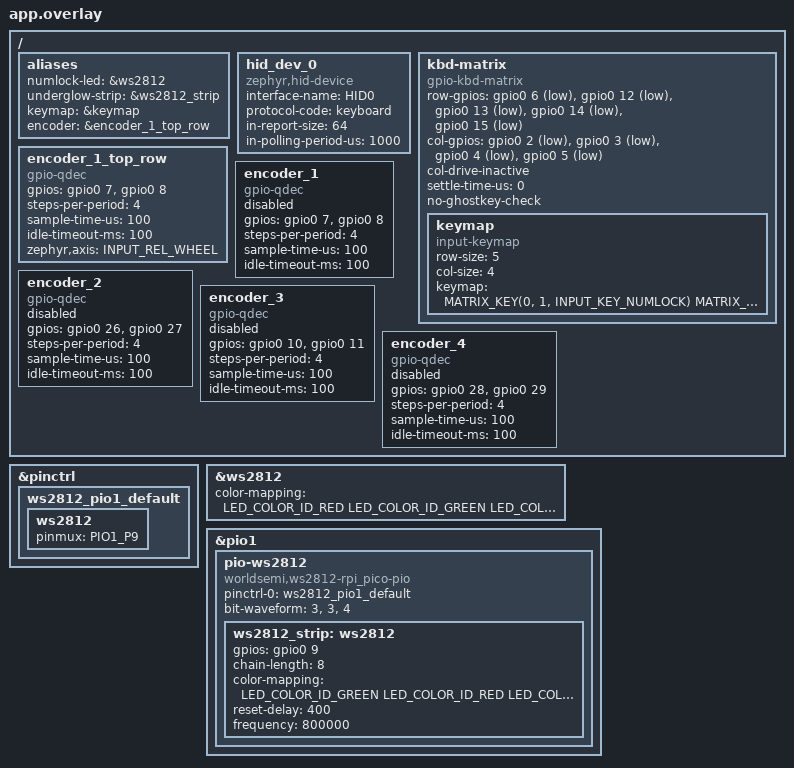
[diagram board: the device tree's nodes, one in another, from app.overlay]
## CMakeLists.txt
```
cmake_minimum_required(VERSION 3.20.0)

set(BOARD rp2040_zero)
find_package(Zephyr)

project(tidbit-gateron)

target_sources(app PRIVATE
  src/main.c
  src/usbd_init.c
)
```

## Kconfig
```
# Copyright (c) 2023 Nordic Semiconductor ASA
# SPDX-License-Identifier: Apache-2.0

menu "USB options"
	depends on USB_DEVICE_STACK_NEXT

config USBD_MANUFACTURER
	string "USB device manufacturer string"
	default "Zephyr Project"
	help
	  USB device manufacturer string.

config USBD_PRODUCT
	string "USB device sample product string"
	default "USBD sample"
	help
	  USB device product stringa.

config USBD_VID
	hex "USB device Vendor ID"
	default 0x2fe3
	help
	  USB device Vendor ID.
	  Zephyr project vendor ID must not be used outside of Zephyr samples.

config USBD_PID
	hex "USB device Product ID"
	default 0x0001
	help
	  USB device Product ID.

config USBD_SELF_POWERED
	bool "USB device Self-powered attribute"
	default y
	help
	  Set the Self-powered attribute in the configuration.

config USBD_REMOTE_WAKEUP
	bool "USB device Remote Wakeup attribute"
	help
	  Set the Remote Wakeup attribute in the configuration.

config USBD_MAX_POWER
	int "USB device bMaxPower value"
	default 125
	range 0 250
	help
	  bMaxPower value in the configuration in 2 mA units.

config USBD_20_EXTENSION_DESC
	bool "Use default USB 2.0 Extension Descriptor"
	help
	  Set bcdUSB value to 0201 and use default USB 2.0 Extension Descriptor.

endmenu

config ENCODER_INVERSE
	bool "Inverse rotary encoder readings"
	help
	  Inverse rotary encoder readings.

source "Kconfig.zephyr"
```

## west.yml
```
manifest:
  remotes:
    - name: zephyrproject-rtos
      url-base: https://github.com/zephyrproject-rtos
  projects:
    - name: zephyr
      remote: zephyrproject-rtos
      revision: v4.1.0
      import:
        name-allowlist:
          - hal_rpi_pico
```

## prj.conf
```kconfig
CONFIG_USB_DEVICE_STACK_NEXT=y
CONFIG_USBD_HID_SUPPORT=y

CONFIG_LOG=y
CONFIG_USBD_LOG_LEVEL_WRN=y
CONFIG_USBD_HID_LOG_LEVEL_WRN=y
CONFIG_UDC_DRIVER_LOG_LEVEL_WRN=y

# VID/PID comes from the used board.
# See: https://github.com/raspberrypi/usb-pid
CONFIG_USBD_VID=0x2E8A
CONFIG_USBD_PID=0x101F
CONFIG_USBD_MANUFACTURER="dseight"
CONFIG_USBD_PRODUCT="tidbit-gateron numpad"

CONFIG_GPIO=y
CONFIG_INPUT=y
CONFIG_INPUT_MODE_SYNCHRONOUS=y

# Inverse rotary encoder readings. Enable for the GREEN encoder.
# CONFIG_ENCODER_INVERSE=y

CONFIG_LED_STRIP=y
```

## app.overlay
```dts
#include <dt-bindings/i2c/i2c.h>
#include <dt-bindings/pinctrl/rpi-pico-rp2040-pinctrl.h>
#include <zephyr/dt-bindings/input/input-event-codes.h>
#include <zephyr/dt-bindings/input/keymap.h>

/ {
	aliases {
		/*
		 * rp2040_zero has a single on-board led, which has "led-strip" alias.
		 * Redefine it as just "led" to reduce confusion.
		 */
		/delete-property/ led-strip;
		numlock-led = &ws2812;
		underglow-strip = &ws2812_strip;
		keymap = &keymap;
		encoder = &encoder_1_top_row;
	};

	hid_dev_0: hid_dev_0 {
		compatible = "zephyr,hid-device";
		interface-name = "HID0";
		protocol-code = "keyboard";
		in-report-size = <64>;
		in-polling-period-us = <1000>;
	};

	kbd-matrix {
		compatible = "gpio-kbd-matrix";
		row-gpios = <&gpio0  6 (GPIO_PULL_UP | GPIO_ACTIVE_LOW)>,
			    <&gpio0 12 (GPIO_PULL_UP | GPIO_ACTIVE_LOW)>,
			    <&gpio0 13 (GPIO_PULL_UP | GPIO_ACTIVE_LOW)>,
			    <&gpio0 14 (GPIO_PULL_UP | GPIO_ACTIVE_LOW)>,
			    <&gpio0 15 (GPIO_PULL_UP | GPIO_ACTIVE_LOW)>;
		col-gpios = <&gpio0 2 GPIO_ACTIVE_LOW>,
			    <&gpio0 3 GPIO_ACTIVE_LOW>,
			    <&gpio0 4 GPIO_ACTIVE_LOW>,
			    <&gpio0 5 GPIO_ACTIVE_LOW>;
		col-drive-inactive;
		settle-time-us = <0>;
		no-ghostkey-check;

		keymap: keymap {
			compatible = "input-keymap";
			row-size = <5>;
			col-size = <4>;
			keymap = <
				MATRIX_KEY(0, 1, INPUT_KEY_NUMLOCK)
				MATRIX_KEY(0, 2, INPUT_KEY_KPSLASH)
				MATRIX_KEY(0, 3, INPUT_KEY_KPASTERISK)

				MATRIX_KEY(1, 0, INPUT_KEY_KP7)
				MATRIX_KEY(1, 1, INPUT_KEY_KP8)
				MATRIX_KEY(1, 2, INPUT_KEY_KP9)
				MATRIX_KEY(1, 3, INPUT_KEY_KPMINUS)

				MATRIX_KEY(2, 0, INPUT_KEY_KP4)
				MATRIX_KEY(2, 1, INPUT_KEY_KP5)
				MATRIX_KEY(2, 2, INPUT_KEY_KP6)
				MATRIX_KEY(2, 3, INPUT_KEY_KPPLUS)

				MATRIX_KEY(3, 0, INPUT_KEY_KP1)
				MATRIX_KEY(3, 1, INPUT_KEY_KP2)
				MATRIX_KEY(3, 2, INPUT_KEY_KP3)
				MATRIX_KEY(3, 3, INPUT_KEY_KPENTER)

				MATRIX_KEY(4, 0, INPUT_KEY_BACKSPACE)
				MATRIX_KEY(4, 1, INPUT_KEY_KP0)
				MATRIX_KEY(4, 2, INPUT_KEY_DOT)
				MATRIX_KEY(4, 3, INPUT_KEY_SYSRQ)
			>;
		};
	};

	encoder_1_top_row: encoder_1_top_row {
		compatible = "gpio-qdec";
		gpios = <&gpio0 7 (GPIO_PULL_UP | GPIO_ACTIVE_HIGH)>,
			<&gpio0 8 (GPIO_PULL_UP | GPIO_ACTIVE_HIGH)>;
		steps-per-period = <4>;
		sample-time-us = <100>;
		idle-timeout-ms = <100>;
		zephyr,axis = <INPUT_REL_WHEEL>;
	};

	encoder_1: encoder_1 {
		compatible = "gpio-qdec";
		gpios = <&gpio0 7 (GPIO_PULL_UP | GPIO_ACTIVE_HIGH)>,
			<&gpio0 8 (GPIO_PULL_UP | GPIO_ACTIVE_HIGH)>;
		steps-per-period = <4>;
		sample-time-us = <100>;
		idle-timeout-ms = <100>;
		status = "disabled";
	};

	encoder_2: encoder_2 {
		compatible = "gpio-qdec";
		gpios = <&gpio0 26 (GPIO_PULL_UP | GPIO_ACTIVE_HIGH)>,
			<&gpio0 27 (GPIO_PULL_UP | GPIO_ACTIVE_HIGH)>;
		steps-per-period = <4>;
		sample-time-us = <100>;
		idle-timeout-ms = <100>;
		status = "disabled";
	};

	encoder_3: encoder_3 {
		compatible = "gpio-qdec";
		gpios = <&gpio0 10 (GPIO_PULL_UP | GPIO_ACTIVE_HIGH)>,
			<&gpio0 11 (GPIO_PULL_UP | GPIO_ACTIVE_HIGH)>;
		steps-per-period = <4>;
		sample-time-us = <100>;
		idle-timeout-ms = <100>;
		status = "disabled";
	};

	encoder_4: encoder_4 {
		compatible = "gpio-qdec";
		gpios = <&gpio0 28 (GPIO_PULL_UP | GPIO_ACTIVE_HIGH)>,
			<&gpio0 29 (GPIO_PULL_UP | GPIO_ACTIVE_HIGH)>;
		steps-per-period = <4>;
		sample-time-us = <100>;
		idle-timeout-ms = <100>;
		status = "disabled";
	};
};

&pinctrl {
	ws2812_pio1_default: ws2812_pio1_default {
		ws2812 {
			pinmux = <PIO1_P9>;
		};
	};
};

&ws2812 {
	/* Color mapping in upstream is wrong */
	color-mapping = <LED_COLOR_ID_RED
			 LED_COLOR_ID_GREEN
			 LED_COLOR_ID_BLUE>;
};

&pio1 {
	status = "okay";

	pio-ws2812 {
		compatible = "worldsemi,ws2812-rpi_pico-pio";
		status = "okay";
		pinctrl-0 = <&ws2812_pio1_default>;
		pinctrl-names = "default";
		bit-waveform = <3>, <3>, <4>;

		ws2812_strip: ws2812 {
			status = "okay";
			gpios = <&gpio0 9 GPIO_ACTIVE_HIGH>;
			chain-length = <8>;
			color-mapping = <LED_COLOR_ID_GREEN
					 LED_COLOR_ID_RED
					 LED_COLOR_ID_BLUE>;
			reset-delay = <400>;
			frequency = <800000>;
		};
	};
};
```

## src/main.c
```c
#include <zephyr/kernel.h>
#include <zephyr/device.h>
#include <zephyr/drivers/gpio.h>
#include <zephyr/drivers/led_strip.h>
#include <zephyr/input/input.h>
#include <zephyr/input/input_hid.h>

#include <zephyr/usb/usbd.h>
#include <zephyr/usb/class/usbd_hid.h>

#include "usbd_init.h"

#define LOG_LEVEL 4
#include <zephyr/logging/log.h>
LOG_MODULE_REGISTER(main);

#define KEYMAP_NODE		DT_ALIAS(keymap)
static const struct device *const keymap_dev = DEVICE_DT_GET(KEYMAP_NODE);

#define ENCODER_NODE		DT_ALIAS(encoder)
static const struct device *const encoder_dev = DEVICE_DT_GET(ENCODER_NODE);

#define UNDERGLOW_NODE		DT_ALIAS(underglow_strip)
static const struct device *const underglow_strip = DEVICE_DT_GET(UNDERGLOW_NODE);

#define NUMLOCK_LED_NODE	DT_ALIAS(numlock_led)
static const struct device *const numlock_led = DEVICE_DT_GET(NUMLOCK_LED_NODE);

#if DT_NODE_HAS_PROP(DT_ALIAS(underglow_strip), chain_length)
#define UNDERGLOW_NUM_PIXELS	DT_PROP(DT_ALIAS(underglow_strip), chain_length)
#else
#error "Unable to determine length of LED strip"
#endif

static struct led_rgb numlock_led_on = {
	.r = 3, .g = 0, .b = 1
};
static struct led_rgb numlock_led_off = {
	.r = 0, .g = 0, .b = 0
};

static const struct led_rgb underglow_idle = {
	.r = 52, .g = 70, .b = 255
};
static const struct led_rgb underglow_numlock_on = {
	.r = 255, .g = 30, .b = 65
};
static struct led_rgb pixels[UNDERGLOW_NUM_PIXELS];

static const uint8_t hid_report_desc[] = HID_KEYBOARD_REPORT_DESC();

enum kb_leds_idx {
	KB_LED_NUMLOCK = 0,
	KB_LED_CAPSLOCK,
	KB_LED_SCROLLLOCK,
	KB_LED_COUNT,
};

enum kb_report_idx {
	KB_MOD_KEY = 0,
	KB_RESERVED,
	KB_KEY_CODE1,
	KB_KEY_CODE2,
	KB_KEY_CODE3,
	KB_KEY_CODE4,
	KB_KEY_CODE5,
	KB_KEY_CODE6,
	KB_REPORT_COUNT,
};

struct kb_event {
	uint8_t type;
	uint16_t code;
	int32_t value;
};

K_MSGQ_DEFINE(kb_msgq, sizeof(struct kb_event), 2, 1);

UDC_STATIC_BUF_DEFINE(report, KB_REPORT_COUNT);
static uint32_t kb_duration;
static bool kb_ready;

static void kb_input_cb(struct input_event *evt, void *user_data)
{
	struct kb_event kb_evt;

	ARG_UNUSED(user_data);

	kb_evt.type = evt->type;
	kb_evt.code = evt->code;
	kb_evt.value = evt->value;
	if (k_msgq_put(&kb_msgq, &kb_evt, K_NO_WAIT) != 0) {
		LOG_ERR("Failed to put new input event");
	}
}
INPUT_CALLBACK_DEFINE(keymap_dev, kb_input_cb, NULL);

static void enc_input_cb(struct input_event *evt, void *user_data)
{
	struct kb_event kb_evt;

	ARG_UNUSED(user_data);

	kb_evt.type = evt->type;
	kb_evt.code = evt->code;
	kb_evt.value = evt->value;
	if (k_msgq_put(&kb_msgq, &kb_evt, K_NO_WAIT) != 0) {
		LOG_ERR("Failed to put new input event");
	}
}
INPUT_CALLBACK_DEFINE(encoder_dev, enc_input_cb, NULL);

static void kb_iface_ready(const struct device *dev, const bool ready)
{
	LOG_INF("HID device %s interface is %s",
		dev->name, ready ? "ready" : "not ready");
	kb_ready = ready;
}

static int kb_get_report(const struct device *dev,
			 const uint8_t type, const uint8_t id, const uint16_t len,
			 uint8_t *const buf)
{
	LOG_WRN("Get Report not implemented, Type %u ID %u", type, id);

	return 0;
}

static int set_underglow_rgb(const struct led_rgb *color)
{
	for (int i = 0; i < UNDERGLOW_NUM_PIXELS; i++)
		pixels[i] = *color;

	return led_strip_update_rgb(underglow_strip, pixels, UNDERGLOW_NUM_PIXELS);
}

static int kb_set_report(const struct device *dev,
			 const uint8_t type, const uint8_t id, const uint16_t len,
			 const uint8_t *const buf)
{
	if (type != HID_REPORT_TYPE_OUTPUT) {
		LOG_WRN("Unsupported report type");
		return -ENOTSUP;
	}

	if (buf[0] & BIT(0)) {
		led_strip_update_rgb(numlock_led, &numlock_led_off, 1);
		set_underglow_rgb(&underglow_idle);
	} else {
		led_strip_update_rgb(numlock_led, &numlock_led_on, 1);
		set_underglow_rgb(&underglow_numlock_on);
	}

	return 0;
}

/* Idle duration is stored but not used to calculate idle reports. */
static void kb_set_idle(const struct device *dev,
			const uint8_t id, const uint32_t duration)
{
	LOG_INF("Set Idle %u to %u", id, duration);
	kb_duration = duration;
}

static uint32_t kb_get_idle(const struct device *dev, const uint8_t id)
{
	LOG_INF("Get Idle %u to %u", id, kb_duration);
	return kb_duration;
}

static void kb_set_protocol(const struct device *dev, const uint8_t proto)
{
	LOG_INF("Protocol changed to %s",
		proto == 0U ? "Boot Protocol" : "Report Protocol");
}

static void kb_output_report(const struct device *dev, const uint16_t len,
			     const uint8_t *const buf)
{
	LOG_HEXDUMP_DBG(buf, len, "o.r.");
	kb_set_report(dev, HID_REPORT_TYPE_OUTPUT, 0U, len, buf);
}

struct hid_device_ops kb_ops = {
	.iface_ready = kb_iface_ready,
	.get_report = kb_get_report,
	.set_report = kb_set_report,
	.set_idle = kb_set_idle,
	.get_idle = kb_get_idle,
	.set_protocol = kb_set_protocol,
	.output_report = kb_output_report,
};

static void msg_cb(struct usbd_context *const usbd_ctx,
		   const struct usbd_msg *const msg)
{
	LOG_INF("USBD message: %s", usbd_msg_type_string(msg->type));

	if (msg->type == USBD_MSG_CONFIGURATION) {
		LOG_INF("\tConfiguration value %d", msg->status);
	}

	if (usbd_can_detect_vbus(usbd_ctx)) {
		if (msg->type == USBD_MSG_VBUS_READY) {
			if (usbd_enable(usbd_ctx)) {
				LOG_ERR("Failed to enable device support");
			}
		}

		if (msg->type == USBD_MSG_VBUS_REMOVED) {
			if (usbd_disable(usbd_ctx)) {
				LOG_ERR("Failed to disable device support");
			}
		}
	}
}

static void handle_kb_event(const struct device *hid_dev,
			    uint16_t code, int32_t value)
{
	int ret;
	int16_t hid_code;

	hid_code = input_to_hid_code(code);
	if (hid_code == -1) {
		LOG_INF("Unrecognized input code %u value %d", code, value);
		return;
	}

	if (value) {
		report[KB_KEY_CODE1] = hid_code;
		report[KB_MOD_KEY] = input_to_hid_modifier(code);
	} else {
		report[KB_KEY_CODE1] = 0;
		report[KB_MOD_KEY] = 0;
	}

	if (!kb_ready) {
		LOG_INF("USB HID device is not ready");
		return;
	}

	ret = hid_device_submit_report(hid_dev, KB_REPORT_COUNT, report);
	if (ret) {
		LOG_ERR("HID submit report error, %d", ret);
	}
}

static void handle_enc_event(const struct device *hid_dev,
			     uint16_t code, int32_t value)
{
	static int enc_events = 0;
	int ret;

	LOG_INF("Encoder event %d value %d", enc_events, value);
	enc_events++;

	if (value != 1 && value != -1) {
		LOG_ERR("Wrong encoder value %d", value);
		return;
	}

	if (IS_ENABLED(CONFIG_ENCODER_INVERSE))
		value = -value;

	report[KB_KEY_CODE1] = HID_KEY_B;
	report[KB_MOD_KEY] = HID_KBD_MODIFIER_LEFT_CTRL;

	ret = hid_device_submit_report(hid_dev, KB_REPORT_COUNT, report);
	if (ret) {
		LOG_ERR("HID submit report error, %d", ret);
		return;
	}

	report[KB_KEY_CODE1] = 0;
	report[KB_MOD_KEY] = 0;

	ret = hid_device_submit_report(hid_dev, KB_REPORT_COUNT, report);
	if (ret) {
		LOG_ERR("HID submit report error, %d", ret);
		return;
	}

	if (value == 1) {
		report[KB_KEY_CODE1] = HID_KEY_N;
		report[KB_MOD_KEY] = 0;
	} else if (value == -1) {
		report[KB_KEY_CODE1] = HID_KEY_P;
		report[KB_MOD_KEY] = 0;
	}

	ret = hid_device_submit_report(hid_dev, KB_REPORT_COUNT, report);
	if (ret) {
		LOG_ERR("HID submit report error, %d", ret);
		return;
	}

	report[KB_KEY_CODE1] = 0;
	report[KB_MOD_KEY] = 0;

	ret = hid_device_submit_report(hid_dev, KB_REPORT_COUNT, report);
	if (ret) {
		LOG_ERR("HID submit report error, %d", ret);
		return;
	}
}

int main(void)
{
	const struct device *hid_dev;
	struct usbd_context *sample_usbd;
	int ret;

	if (!device_is_ready(underglow_strip)) {
		LOG_ERR("LED strip device %s is not ready", underglow_strip->name);
		return 0;
	}

	hid_dev = DEVICE_DT_GET_ONE(zephyr_hid_device);
	if (!device_is_ready(hid_dev)) {
		LOG_ERR("HID Device is not ready");
		return -EIO;
	}

	ret = hid_device_register(hid_dev,
				  hid_report_desc, sizeof(hid_report_desc),
				  &kb_ops);
	if (ret != 0) {
		LOG_ERR("Failed to register HID Device, %d", ret);
		return ret;
	}

	sample_usbd = sample_usbd_init_device(msg_cb);
	if (sample_usbd == NULL) {
		LOG_ERR("Failed to initialize USB device");
		return -ENODEV;
	}

	if (!usbd_can_detect_vbus(sample_usbd)) {
		/* doc device enable start */
		ret = usbd_enable(sample_usbd);
		if (ret) {
			LOG_ERR("Failed to enable device support");
			return ret;
		}
		/* doc device enable end */
	}

	LOG_INF("HID keyboard is initialized");

	while (true) {
		struct kb_event kb_evt;

		k_msgq_get(&kb_msgq, &kb_evt, K_FOREVER);

		switch (kb_evt.type) {
		case INPUT_EV_KEY:
			handle_kb_event(hid_dev, kb_evt.code, kb_evt.value);
			break;
		case INPUT_EV_REL:
			handle_enc_event(hid_dev, kb_evt.code, kb_evt.value);
			break;
		default:
			LOG_INF("Enexpected event type %u", kb_evt.type);
		}

	}

	return 0;
}
```

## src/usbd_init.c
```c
/*
 * Copyright (c) 2023 Nordic Semiconductor ASA
 *
 * SPDX-License-Identifier: Apache-2.0
 */

#include <stdint.h>

#include <zephyr/device.h>
#include <zephyr/usb/usbd.h>
#include <zephyr/usb/bos.h>

#include <zephyr/logging/log.h>
LOG_MODULE_REGISTER(usbd_sample_config);

/* By default, do not register the USB DFU class DFU mode instance. */
static const char *const blocklist[] = {
	"dfu_dfu",
	NULL,
};

/* doc device instantiation start */
/*
 * Instantiate a context named sample_usbd using the default USB device
 * controller, the Zephyr project vendor ID, and the sample product ID.
 * Zephyr project vendor ID must not be used outside of Zephyr samples.
 */
USBD_DEVICE_DEFINE(sample_usbd,
		   DEVICE_DT_GET(DT_NODELABEL(zephyr_udc0)),
		   CONFIG_USBD_VID, CONFIG_USBD_PID);
/* doc device instantiation end */

/* doc string instantiation start */
USBD_DESC_LANG_DEFINE(sample_lang);
USBD_DESC_MANUFACTURER_DEFINE(sample_mfr, CONFIG_USBD_MANUFACTURER);
USBD_DESC_PRODUCT_DEFINE(sample_product, CONFIG_USBD_PRODUCT);
USBD_DESC_SERIAL_NUMBER_DEFINE(sample_sn);
/* doc string instantiation end */

USBD_DESC_CONFIG_DEFINE(fs_cfg_desc, "FS Configuration");
USBD_DESC_CONFIG_DEFINE(hs_cfg_desc, "HS Configuration");

/* doc configuration instantiation start */
static const uint8_t attributes = (IS_ENABLED(CONFIG_USBD_SELF_POWERED) ?
				   USB_SCD_SELF_POWERED : 0) |
				  (IS_ENABLED(CONFIG_USBD_REMOTE_WAKEUP) ?
				   USB_SCD_REMOTE_WAKEUP : 0);

/* Full speed configuration */
USBD_CONFIGURATION_DEFINE(sample_fs_config,
			  attributes,
			  CONFIG_USBD_MAX_POWER, &fs_cfg_desc);

/* High speed configuration */
USBD_CONFIGURATION_DEFINE(sample_hs_config,
			  attributes,
			  CONFIG_USBD_MAX_POWER, &hs_cfg_desc);
/* doc configuration instantiation end */

/*
 * This does not yet provide valuable information, but rather serves as an
 * example, and will be improved in the future.
 */
static const struct usb_bos_capability_lpm bos_cap_lpm = {
	.bLength = sizeof(struct usb_bos_capability_lpm),
	.bDescriptorType = USB_DESC_DEVICE_CAPABILITY,
	.bDevCapabilityType = USB_BOS_CAPABILITY_EXTENSION,
	.bmAttributes = 0UL,
};

USBD_DESC_BOS_DEFINE(sample_usbext, sizeof(bos_cap_lpm), &bos_cap_lpm);

static void sample_fix_code_triple(struct usbd_context *uds_ctx,
				   const enum usbd_speed speed)
{
	/* Always use class code information from Interface Descriptors */
	if (IS_ENABLED(CONFIG_USBD_CDC_ACM_CLASS) ||
	    IS_ENABLED(CONFIG_USBD_CDC_ECM_CLASS) ||
	    IS_ENABLED(CONFIG_USBD_CDC_NCM_CLASS) ||
	    IS_ENABLED(CONFIG_USBD_MIDI2_CLASS) ||
	    IS_ENABLED(CONFIG_USBD_AUDIO2_CLASS)) {
		/*
		 * Class with multiple interfaces have an Interface
		 * Association Descriptor available, use an appropriate triple
		 * to indicate it.
		 */
		usbd_device_set_code_triple(uds_ctx, speed,
					    USB_BCC_MISCELLANEOUS, 0x02, 0x01);
	} else {
		usbd_device_set_code_triple(uds_ctx, speed, 0, 0, 0);
	}
}

struct usbd_context *sample_usbd_setup_device(usbd_msg_cb_t msg_cb)
{
	int err;

	/* doc add string descriptor start */
	err = usbd_add_descriptor(&sample_usbd, &sample_lang);
	if (err) {
		LOG_ERR("Failed to initialize language descriptor (%d)", err);
		return NULL;
	}

	err = usbd_add_descriptor(&sample_usbd, &sample_mfr);
	if (err) {
		LOG_ERR("Failed to initialize manufacturer descriptor (%d)", err);
		return NULL;
	}

	err = usbd_add_descriptor(&sample_usbd, &sample_product);
	if (err) {
		LOG_ERR("Failed to initialize product descriptor (%d)", err);
		return NULL;
	}

	err = usbd_add_descriptor(&sample_usbd, &sample_sn);
	if (err) {
		LOG_ERR("Failed to initialize SN descriptor (%d)", err);
		return NULL;
	}
	/* doc add string descriptor end */

	if (usbd_caps_speed(&sample_usbd) == USBD_SPEED_HS) {
		err = usbd_add_configuration(&sample_usbd, USBD_SPEED_HS,
					     &sample_hs_config);
		if (err) {
			LOG_ERR("Failed to add High-Speed configuration");
			return NULL;
		}

		err = usbd_register_all_classes(&sample_usbd, USBD_SPEED_HS, 1,
						blocklist);
		if (err) {
			LOG_ERR("Failed to add register classes");
			return NULL;
		}

		sample_fix_code_triple(&sample_usbd, USBD_SPEED_HS);
	}

	/* doc configuration register start */
	err = usbd_add_configuration(&sample_usbd, USBD_SPEED_FS,
				     &sample_fs_config);
	if (err) {
		LOG_ERR("Failed to add Full-Speed configuration");
		return NULL;
	}
	/* doc configuration register end */

	/* doc functions register start */
	err = usbd_register_all_classes(&sample_usbd, USBD_SPEED_FS, 1, blocklist);
	if (err) {
		LOG_ERR("Failed to add register classes");
		return NULL;
	}
	/* doc functions register end */

	sample_fix_code_triple(&sample_usbd, USBD_SPEED_FS);
	usbd_self_powered(&sample_usbd, attributes & USB_SCD_SELF_POWERED);

	if (msg_cb != NULL) {
		/* doc device init-and-msg start */
		err = usbd_msg_register_cb(&sample_usbd, msg_cb);
		if (err) {
			LOG_ERR("Failed to register message callback");
			return NULL;
		}
		/* doc device init-and-msg end */
	}

	if (IS_ENABLED(CONFIG_USBD_20_EXTENSION_DESC)) {
		(void)usbd_device_set_bcd_usb(&sample_usbd, USBD_SPEED_FS, 0x0201);
		(void)usbd_device_set_bcd_usb(&sample_usbd, USBD_SPEED_HS, 0x0201);

		err = usbd_add_descriptor(&sample_usbd, &sample_usbext);
		if (err) {
			LOG_ERR("Failed to add USB 2.0 Extension Descriptor");
			return NULL;
		}
	}

	return &sample_usbd;
}

struct usbd_context *sample_usbd_init_device(usbd_msg_cb_t msg_cb)
{
	int err;

	if (sample_usbd_setup_device(msg_cb) == NULL) {
		return NULL;
	}

	/* doc device init start */
	err = usbd_init(&sample_usbd);
	if (err) {
		LOG_ERR("Failed to initialize device support");
		return NULL;
	}
	/* doc device init end */

	return &sample_usbd;
}
```

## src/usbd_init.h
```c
#pragma once

struct usbd_context *sample_usbd_init_device(usbd_msg_cb_t msg_cb);
```
